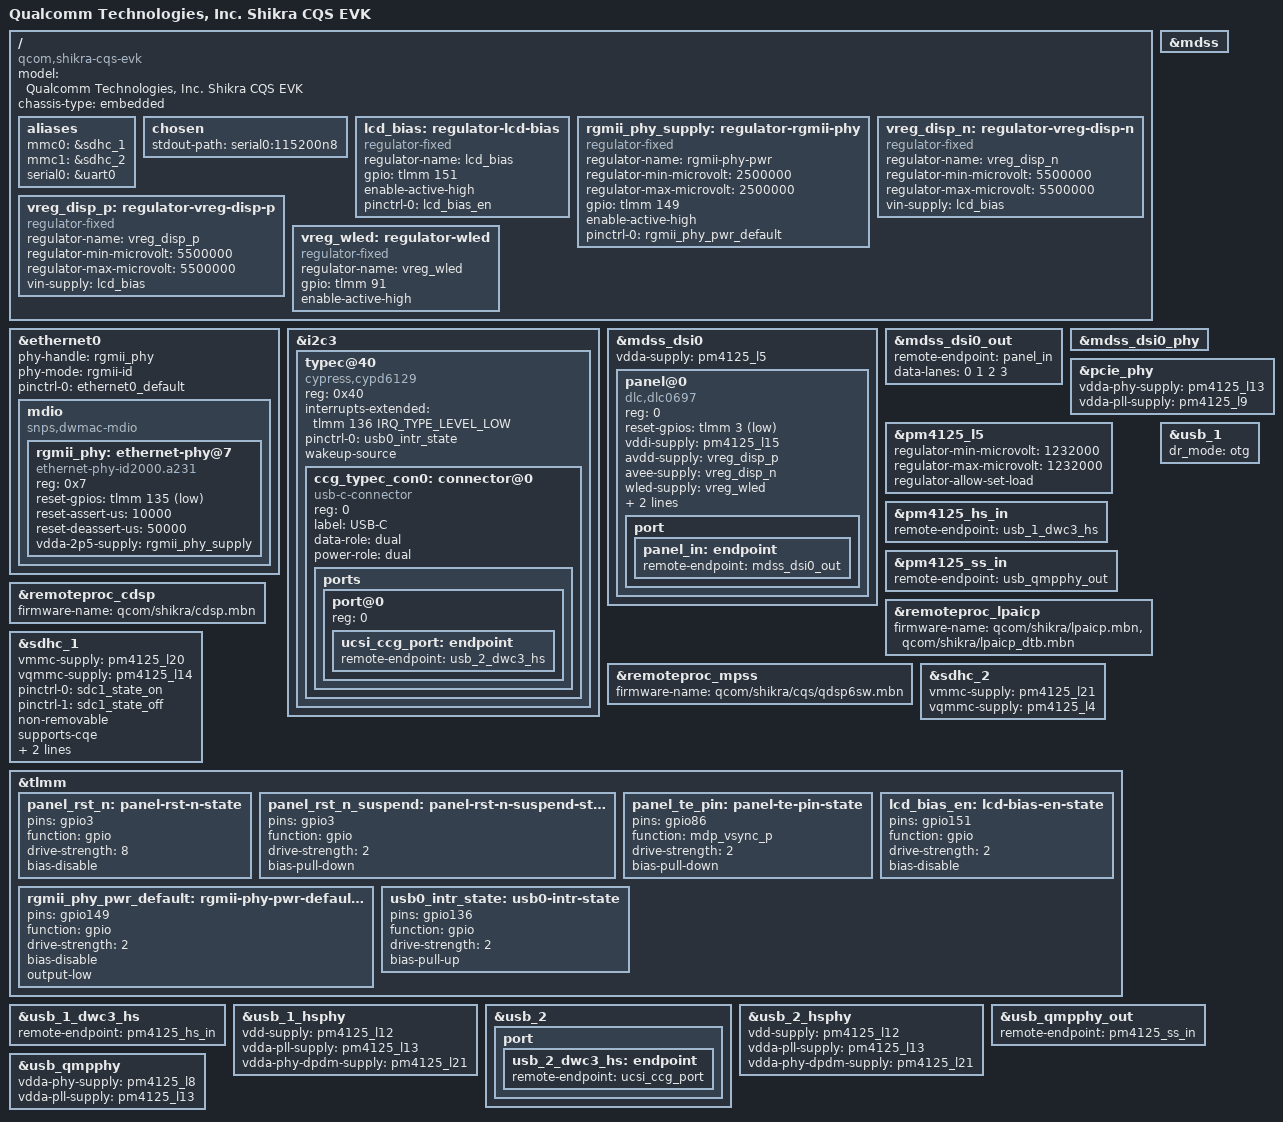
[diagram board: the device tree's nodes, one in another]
// SPDX-License-Identifier: BSD-3-Clause
/*
 * Copyright (c) Qualcomm Technologies, Inc. and/or its subsidiaries.
 */

/dts-v1/;

#include "shikra-cqm-som.dtsi"
#include "shikra-evk.dtsi"
#include <dt-bindings/gpio/gpio.h>

/ {
	model = "Qualcomm Technologies, Inc. Shikra CQS EVK";
	compatible = "qcom,shikra-cqs-evk", "qcom,shikra-cqs-som", "qcom,shikra";
	chassis-type = "embedded";

	aliases {
		mmc0 = &sdhc_1;
		mmc1 = &sdhc_2; /* SDC2 SD card slot */
		serial0 = &uart0;
	};

	chosen {
		stdout-path = "serial0:115200n8";
	};

	lcd_bias: regulator-lcd-bias {
		compatible = "regulator-fixed";
		regulator-name = "lcd_bias";
		gpio = <&tlmm 151 GPIO_ACTIVE_HIGH>;
		enable-active-high;
		pinctrl-0 = <&lcd_bias_en>;
		pinctrl-names = "default";
	};

	rgmii_phy_supply: regulator-rgmii-phy {
		compatible = "regulator-fixed";
		regulator-name = "rgmii-phy-pwr";
		regulator-min-microvolt = <2500000>;
		regulator-max-microvolt = <2500000>;
		gpio = <&tlmm 149 GPIO_ACTIVE_HIGH>;
		enable-active-high;
		pinctrl-0 = <&rgmii_phy_pwr_default>;
		pinctrl-names = "default";
	};

	vreg_disp_n: regulator-vreg-disp-n {
		compatible = "regulator-fixed";
		regulator-name = "vreg_disp_n";
		regulator-min-microvolt = <5500000>;
		regulator-max-microvolt = <5500000>;
		vin-supply = <&lcd_bias>;
	};

	vreg_disp_p: regulator-vreg-disp-p {
		compatible = "regulator-fixed";
		regulator-name = "vreg_disp_p";
		regulator-min-microvolt = <5500000>;
		regulator-max-microvolt = <5500000>;
		vin-supply = <&lcd_bias>;
	};

	vreg_wled: regulator-wled {
		compatible = "regulator-fixed";
		regulator-name = "vreg_wled";
		gpio = <&tlmm 91 GPIO_ACTIVE_HIGH>;
		enable-active-high;
	};
};

&ethernet0 {
	phy-handle = <&rgmii_phy>;
	phy-mode = "rgmii-id";

	pinctrl-0 = <&ethernet0_default>;
	pinctrl-names = "default";

	status = "okay";

	mdio {
		compatible = "snps,dwmac-mdio";
		#address-cells = <1>;
		#size-cells = <0>;

		rgmii_phy: ethernet-phy@7 {
			compatible = "ethernet-phy-id2000.a231";
			reg = <0x7>;
			reset-gpios = <&tlmm 135 GPIO_ACTIVE_LOW>;
			reset-assert-us = <10000>;
			reset-deassert-us = <50000>;
			vdda-2p5-supply = <&rgmii_phy_supply>;
		};
	};
};

&i2c3 {
	status = "okay";

	typec@40 {
		compatible = "cypress,cypd6129";
		reg = <0x40>;
		interrupts-extended = <&tlmm 136 IRQ_TYPE_LEVEL_LOW>;
		pinctrl-0 = <&usb0_intr_state>;
		pinctrl-names = "default";
		wakeup-source;

		#address-cells = <1>;
		#size-cells = <0>;

		ccg_typec_con0: connector@0 {
			compatible = "usb-c-connector";
			reg = <0>;
			label = "USB-C";
			data-role = "dual";
			power-role = "dual";

			ports {
				#address-cells = <1>;
				#size-cells = <0>;

				port@0 {
					reg = <0>;

					ucsi_ccg_port: endpoint {
						remote-endpoint = <&usb_2_dwc3_hs>;
					};
				};
			};
		};
	};
};

&mdss {
	status = "okay";
};

&mdss_dsi0 {
	vdda-supply = <&pm4125_l5>;

	status = "okay";

	panel@0 {
		compatible = "dlc,dlc0697", "ilitek,ili7807s";
		reg = <0>;

		reset-gpios = <&tlmm 3 GPIO_ACTIVE_LOW>;

		vddi-supply = <&pm4125_l15>;
		avdd-supply = <&vreg_disp_p>;
		avee-supply = <&vreg_disp_n>;
		wled-supply = <&vreg_wled>;

		pinctrl-0 = <&panel_rst_n &panel_te_pin>;
		pinctrl-1 = <&panel_rst_n_suspend>;
		pinctrl-names = "default", "sleep";

		port {
			panel_in: endpoint {
				remote-endpoint = <&mdss_dsi0_out>;
			};
		};
	};
};

&mdss_dsi0_out {
	remote-endpoint = <&panel_in>;
	data-lanes = <0 1 2 3>;
};

&mdss_dsi0_phy {
	status = "okay";
};

&pcie_phy {
	vdda-phy-supply = <&pm4125_l13>;
	vdda-pll-supply = <&pm4125_l9>;

	status = "okay";
};

&pm4125_l5 {
	/* DSI VDDA - must be at NOM voltage for PHY PLL lock */
	regulator-min-microvolt = <1232000>;
	regulator-max-microvolt = <1232000>;
	regulator-allow-set-load;
};

&pm4125_hs_in {
	remote-endpoint = <&usb_1_dwc3_hs>;
};

&pm4125_ss_in {
	remote-endpoint = <&usb_qmpphy_out>;
};

&remoteproc_cdsp {
	firmware-name = "qcom/shikra/cdsp.mbn";

	status = "okay";
};

&remoteproc_lpaicp {
	firmware-name = "qcom/shikra/lpaicp.mbn",
			"qcom/shikra/lpaicp_dtb.mbn";

	status = "okay";
};

&remoteproc_mpss {
	firmware-name = "qcom/shikra/cqs/qdsp6sw.mbn";

	status = "okay";
};

&sdhc_1 {
	vmmc-supply = <&pm4125_l20>;
	vqmmc-supply = <&pm4125_l14>;

	pinctrl-0 = <&sdc1_state_on>;
	pinctrl-1 = <&sdc1_state_off>;
	pinctrl-names = "default", "sleep";

	non-removable;
	supports-cqe;
	no-sdio;
	no-sd;

	status = "okay";
};

&sdhc_2 {
	vmmc-supply = <&pm4125_l21>;
	vqmmc-supply = <&pm4125_l4>;

	status = "okay";
};

&tlmm {
	panel_rst_n: panel-rst-n-state {
		pins = "gpio3";
		function = "gpio";
		drive-strength = <8>;
		bias-disable;
	};

	panel_rst_n_suspend: panel-rst-n-suspend-state {
		pins = "gpio3";
		function = "gpio";
		drive-strength = <2>;
		bias-pull-down;
	};

	panel_te_pin: panel-te-pin-state {
		pins = "gpio86";
		function = "mdp_vsync_p";
		drive-strength = <2>;
		bias-pull-down;
	};

	lcd_bias_en: lcd-bias-en-state {
		pins = "gpio151";
		function = "gpio";
		drive-strength = <2>;
		bias-disable;
	};

	rgmii_phy_pwr_default: rgmii-phy-pwr-default-state {
		pins = "gpio149";
		function = "gpio";
		drive-strength = <2>;
		bias-disable;
		output-low;
	};

	usb0_intr_state: usb0-intr-state {
		pins = "gpio136";
		function = "gpio";
		drive-strength = <2>;
		bias-pull-up;
	};
};

&usb_1 {
	/delete-property/ dr_mode;
	dr_mode = "otg";
};

&usb_1_dwc3_hs {
	remote-endpoint = <&pm4125_hs_in>;
};

&usb_1_hsphy {
	vdd-supply = <&pm4125_l12>;
	vdda-pll-supply = <&pm4125_l13>;
	vdda-phy-dpdm-supply = <&pm4125_l21>;

	status = "okay";
};

&usb_2 {
	/delete-property/ dr_mode;

	port {
		usb_2_dwc3_hs: endpoint {
			remote-endpoint = <&ucsi_ccg_port>;
		};
	};
};

&usb_2_hsphy {
	vdd-supply = <&pm4125_l12>;
	vdda-pll-supply = <&pm4125_l13>;
	vdda-phy-dpdm-supply = <&pm4125_l21>;

	status = "okay";
};

&usb_qmpphy_out {
	remote-endpoint = <&pm4125_ss_in>;
};

&usb_qmpphy {
	vdda-phy-supply = <&pm4125_l8>;
	vdda-pll-supply = <&pm4125_l13>;

	status = "okay";
};
